# nrf9230_cellcore register map
Vendor: Nordic Semiconductor; Series: nRF92; File version: 1
CPU: CM33 r0p4, little endian, MPU, FPU, 3 interrupt priority bits, 480 interrupts, 8 SAU regions
Registers are 32-bit, read-write, reset 0x0 unless marked. A register's access mark holds for its fields unless they carry their own. Offsets are from the block's base; [hi:lo] are bit positions; lines under a group give offsets from that group; {n}, {i} and the like mark numbered series; 'fields as' and 'values as' point back to an identical list.

## MCPLL_NS — Modem Clock PLL 0
Base 0x44035000
Same registers: MCPLL_S 0x54035000
0x00 TASKS_START wo — Start MCPLL
  [0] TASKS_START
    1=Trigger task
0x04 TASKS_UPDATE wo — Update CONTROL.FRAC and CONTROL.INT values
  [0] TASKS_UPDATE
    1=Trigger task
0x08 TASKS_STOP wo — Cancels the START task. MCPLL may be still enabled if requested by HW.
  [0] TASKS_STOP
    1=Trigger task
0x100 EVENTS_STARTED — MCPLL start sequence completed. Clock is running.
  [0] EVENTS_STARTED
    0=NotGenerated (Event not generated); 1=Generated (Event generated)
0x104 EVENTS_LOCKTIMEOUT — Error event, lock was not achieved in given timeout limit (LOCKTIMEOUT)
  [0] EVENTS_LOCKTIMEOUT
    values as EVENTS_STARTED.EVENTS_STARTED
0x108 EVENTS_LOCKLOST — Error event, MCPLL no longer in lock
  [0] EVENTS_LOCKLOST
    values as EVENTS_STARTED.EVENTS_STARTED
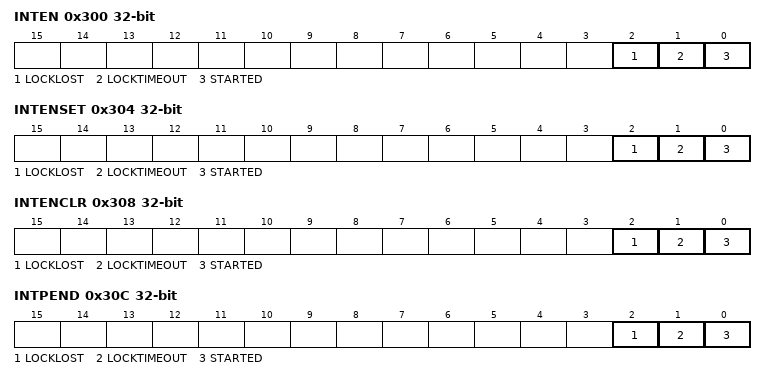
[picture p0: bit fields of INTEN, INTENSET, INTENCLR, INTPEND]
0x300 INTEN — Enable or disable interrupt
  [all] fields
    0=Disabled; 1=Enabled
  [2] LOCKLOST — Enable or disable interrupt for event LOCKLOST
  [1] LOCKTIMEOUT — Enable or disable interrupt for event LOCKTIMEOUT
  [0] STARTED — Enable or disable interrupt for event STARTED
0x304 INTENSET — Enable interrupt
  [all] fields
    on read: 0=Disabled (Read: Disabled); 1=Enabled (Read: Enabled) | on write: 1=Set (Enable)
  [2] LOCKLOST — Write '1' to enable interrupt for event LOCKLOST
  [1] LOCKTIMEOUT — Write '1' to enable interrupt for event LOCKTIMEOUT
  [0] STARTED — Write '1' to enable interrupt for event STARTED
0x308 INTENCLR — Disable interrupt
  [all] fields
    on read: 0=Disabled (Read: Disabled); 1=Enabled (Read: Enabled) | on write: 1=Clear (Disable)
  [2] LOCKLOST — Write '1' to disable interrupt for event LOCKLOST
  [1] LOCKTIMEOUT — Write '1' to disable interrupt for event LOCKTIMEOUT
  [0] STARTED — Write '1' to disable interrupt for event STARTED
0x30C INTPEND ro — Pending interrupts
  [all] fields
    on read: 0=NotPending (Read: Not pending); 1=Pending (Read: Pending)
  [2] LOCKLOST — Read pending status of interrupt for event LOCKLOST
  [1] LOCKTIMEOUT — Read pending status of interrupt for event LOCKTIMEOUT
  [0] STARTED — Read pending status of interrupt for event STARTED
0x400 INLOCK ro — Status bit for MCPLL inlock signal
  [0] INLOCK — MCPLL locked or not
    0=NotInLock (MCPLL not locked); 1=InLock (MCPLL locked)
0x404 REQ_MCPLL_STATUS ro — Status bit for REQ_MCPLL input signal
  [0] REQ_MCPLL_STATUS — MCPLL requested by HW or not
    0=NoRequest (MCPLL not requested by HW); 1=Requested (MCPLL requested by HW)
0x408 FSM_STATUS ro — Current state of MCPLL FSM
  [4:0] FSM_STATUS — state
    0=Idle (No request); 1=StartXo (Request crystal and wait until crystal is settled); 2=StartMcpll (Enable levelshifters and assert SDM digital reset); 3=StartLdo (Enable LDO); 4=StartCore (Enable analog core); 5=StartSdm (Enable sigmadelta modulator); 6=FCWUpdate (Fetch division word from register); 7=FCWSettle (Wait frequency to settle); 8=EnaOutputs (Enable output buffers); 9=Run (Enable lock detector); 10=Ready (Lock detected. Everything ready.); 11=StopLockdet (Disable lock detector); 12=StopSdm (Disable SDM); 13=StopLdo (Disable LDO); 14=StopCore (Disable analog core); 15=StopMcpll (Disable levelshifters and assert SDM digital reset); 16=StopXo (Stop requesting crystal)
0x40C CLEANPWR_ACK ro — Status of the clean power ack
  [0] CLEANPWR_ACK — Status of the clean power ack. Clean power can be requested with CLEANPWR_REQ.
    0=NACK (Clean power not yet available or not requested); 1=ACK (Clean power available)
0x410 HFXO_STATUS ro — Status of the HfXo
  [0] READY — Status of the HfXo.
    0=NotReady (HfXo is not available.); 1=Ready (HfXo ready)
0x504 CONTROL group — Unspecified
  0x00 INT reset 0x12 — Integer part of the control word.
    [5:0] INT — Integer part of the control word
  0x04 FRAC reset 0x199999 — Fractional part of the control word.
    [22:0] FRAC — Fractional part of the control word
0x510 MA reset 0x3 — Post division ratio for OUTA (LTETIMER and CELLRF)
  [2:0] MA
    0=Nothing (Output grounded, constant logic low); 1=CLK307M2 (Division by 16, output frequency is 307.2 MHz); 2=Nothing2 (Output grounded, constant logic low); 3=CLK122M88 (Division by 40, output frequency is 122.88 MHz); 4=CLK153M6 (Division by 32, output frequency is 153.6 MHz); 5=ExtClk (External clock); 6=Nothing3 (Output grounded, constant logic low); 7=Nothing4 (Output grounded, constant logic low)
0x514 MB reset 0x1 — Post division ratio for OUTB (TX DAC in CELLRF)
  [2:0] MB
    0=Nothing (Output grounded, constant logic low); 1=CLK307M2 (Division by 16, output frequency is 307.2 MHz); 2=Nothing2 (Output grounded, constant logic low); 3=Nothing3 (Output grounded, constant logic low); 4=CLK153M6 (Division by 32, output frequency is 153.6 MHz); 5=ExtClk (External clock); 6=Nothing4 (Output grounded, constant logic low); 7=Nothing5 (Output grounded, constant logic low)
0x518 MC reset 0x1 — Post division ratio for OUTC (RX ADC in CELLRF)
  [2:0] MC — Post division ratio for OUTC (RX ADC in CELLRF). Depending on MC_TRIG register a external trigger is required. Changing the division factor between 15 and 16 on the fly is not glitch free. If division factor is switched between 16 and 15 it must be ensured that the receiver of the clock is disabled at that moment.
    0=Nothing (Output grounded, constant logic low); 1=CLK307M2 (Division by 16, output frequency is 307.2 MHz); 2=CLK327M68 (Division by 15, output frequency is 327.68 MHz); 3=Nothing2 (Output grounded, constant logic low); 4=CLK153M6 (Division by 32, output frequency is 153.6 MHz); 5=ExtClk (External clock); 6=Nothing3 (Output grounded, constant logic low); 7=Nothing4 (Output grounded, constant logic low)
0x51C MD — Post division ratio for OUTD (Unused)
  [2:0] MD
    values as MC.MC
0x520 MTESTOUT — Post division ratio for Testout
  [2:0] MTESTOUT — Post division ratio for Testout (Connected to IO)
    0=Nothing (Output grounded, constant logic low); 1=CLK307M2 (Division by 16, output frequency is 307.2 MHz); 2=CLK327M68 (Division by 15, output frequency is 327.68 MHz); 3=CLK122M88 (Division by 40, output frequency is 122.88 MHz); 4=CLK153M6 (Division by 32, output frequency is 153.6 MHz); 5=ExtClk (External clock); 6=Nothing2 (Output grounded, constant logic low); 7=Nothing3 (Output grounded, constant logic low)
0x524 MCTRIG — MC register triggering setting
  [0] MCTRIG_ENA — Enable for MC register triggering
    0=NORMAL (MC register changes division setting immediately); 1=TRIGGER (MC register requires pulse from REQ_MC input before division setting is applied)
0x528 REQUPDATE — REQ_UPDATE setting
  [0] REQ_UPDATE_ENA — Disable for REQ_UPDATE
    0=NORMAL (REQ_UPDATE from HW updates FCW normally); 1=BLOCK (REQ_UPDATE from HW is blocked and doesn`t update FCW)
0x530 TRIM — MCPLL trimming
  [3:0] LDO_RTUNE — LDO reference voltage tuning against process corners. See analog IP specification.
0x534 OVERRIDE group — Override mechanism
  0x00 INLOCK — Override for MCPLL inLock
    [0] FORCEINLOCK — Force inlock value from analog to high
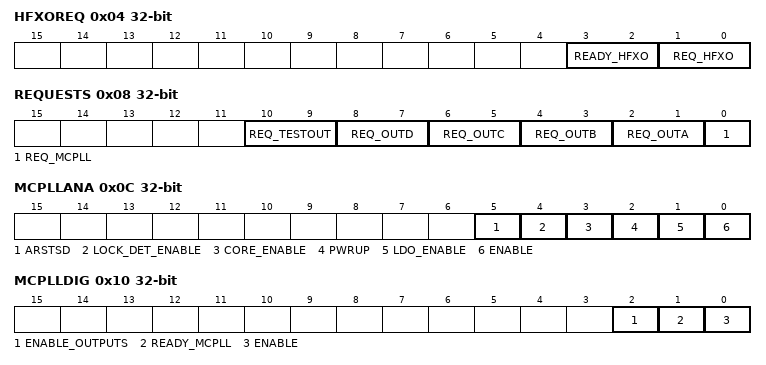
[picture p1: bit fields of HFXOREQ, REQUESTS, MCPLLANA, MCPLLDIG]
  0x04 HFXOREQ — Override for HFXO controls
    [3:2] READY_HFXO — Override for HFXO ready
      0=NORMAL (Ready is provided by crystal to MCPLL FSM); 1=UNUSED (Ready is provided by crystal to MCPLL FSM); 2=BLOCKED (Ready signal from crystal is forced low); 3=FORCED (Ready signal from crystal is forced high)
    [1:0] REQ_HFXO — Override for HFXO request
      0=NORMAL (Crystal is requested according to MCPLL FSM); 1=UNUSED (Crystal is requested according to MCPLL FSM); 2=BLOCKED (Crystal is not requested); 3=FORCED (Crystal is requested)
  0x08 REQUESTS — Override for request signals
    [10:9] REQ_TESTOUT — Override for REQ_TESTOUT
      0=NORMAL (REQ_TESTOUT from HW requests TESTOUT normally); 1=UNUSED (REQ_TESTOUT from HW requests TESTOUT normally); 2=BLOCKED (REQ_TESTOUT from HW is blocked and TESTOUT buffer is disabled); 3=FORCED (REQ_TESTOUT from HW is forced and TESTOUT buffer is enabled)
    [8:7] REQ_OUTD — Override for REQ_OUTD
      0=NORMAL (REQ_OUTD from HW requests OUTD normally); 1=UNUSED (REQ_OUTD from HW requests OUTD normally); 2=BLOCKED (REQ_OUTD from HW is blocked and OUTD buffer is disabled); 3=FORCED (REQ_OUTD from HW is forced and OUTD buffer is enabled)
    [6:5] REQ_OUTC — Override for REQ_OUTC
      0=NORMAL (REQ_OUTC from HW requests OUTC normally); 1=UNUSED (REQ_OUTC from HW requests OUTC normally); 2=BLOCKED (REQ_OUTC from HW is blocked and OUTC buffer is disabled); 3=FORCED (REQ_OUTC from HW is forced and OUTC buffer is enabled)
    [4:3] REQ_OUTB — Override for REQ_OUTB
      0=NORMAL (REQ_OUTB from HW requests OUTB normally); 1=UNUSED (REQ_OUTB from HW requests OUTB normally); 2=BLOCKED (REQ_OUTB from HW is blocked and OUTB buffer is disabled); 3=FORCED (REQ_OUTB from HW is forced and OUTB buffer is enabled)
    [2:1] REQ_OUTA — Override for REQ_OUTA
      0=NORMAL (REQ_OUTA from HW requests OUTA normally); 1=UNUSED (REQ_OUTA from HW requests OUTA normally); 2=BLOCKED (REQ_OUTA from HW is blocked and OUTA buffer is disabled); 3=FORCED (REQ_OUTA from HW is forced and OUTA buffer is enabled)
    [0] REQ_MCPLL — Override for REQ_MCPLL
      0=NORMAL (REQ_MCPLL from HW requests MCPLL normally); 1=BLOCK (REQ_MCPLL from HW is blocked and doesn`t start MCPLL)
  0x0C MCPLLANA — Override for MCPLL analog controls
    [5] ARSTSD — Override for MCPLL sigmadelta modulator reset
      0=OFF (Force ARSTSD low); 1=ON (Force ARSTSD high)
    [4] LOCK_DET_ENABLE — Override for LOCK_DET_ENABLE
      0=OFF (Force LOCK_DET_ENABLE low); 1=ON (Force LOCK_DET_ENABLE high)
    [3] CORE_ENABLE — Override for CORE_ENABLE
      0=OFF (Force CORE_ENABLE low); 1=ON (Force CORE_ENABLE high)
    [2] PWRUP — Override for PWRUP_MCPLL
      0=OFF (Force PWRUP_MCPLL low); 1=ON (Force PWRUP_MCPLL high)
    [1] LDO_ENABLE — LDO enable override value
      0=OFF (Force LDO_ENABLE low); 1=ON (Force LDO_ENABLE high)
    [0] ENABLE — Enable override
      0=No override enabled; 1=Override (All overrides in this register are enabled)
  0x10 MCPLLDIG — Override for MCPLL digital controls
    [2] ENABLE_OUTPUTS — Fsm enableOutputs override
      0=Disabled (Force enableOutputs low); 1=Enabled (Force enableOutputs high)
    [1] READY_MCPLL — Fsm readyMcpll override
      0=LOW (Force readyMcpll low); 1=HIGH (Force readyMcpll high)
    [0] ENABLE — Enable override
      values as OVERRIDE.MCPLLANA.ENABLE
0x550 OUTA_DRV reset 0x1 — Drive strength for OUTA
  [1:0] OUTA_DRV
0x554 OUTB_DRV reset 0x1 — Drive strength for OUTB
  [1:0] OUTB_DRV
0x558 OUTC_DRV reset 0x1 — Drive strength for OUTC
  [1:0] OUTC_DRV
0x55C OUTD_DRV reset 0x1 — Drive strength for OUTD
  [1:0] OUTD_DRV
0x560 OUTTEST_DRV reset 0x1 — Drive strength for Testout
  [1:0] OUTTEST_DRV
0x570 INTMODE — Integer mode
  [0] INTMODE
    0=Fractional mode; 1=Integer mode
0x580 LOCKTIMEOUT — Timeout value for locking
  [1:0] LOCKTIMEOUT
    0=VALUE20US (If locking takes more than 20us, LOCKTIMEOUT event is generated.); 1=VALUE40US (If locking takes more than 40us, LOCKTIMEOUT event is generated.); 2=VALUE60US (If locking takes more than 60us, LOCKTIMEOUT event is generated.); 3=UNLIMITED (Lock signal is waited forever)
0x590 EXTCLK — External clock control
  [0] EXTCLKENABLE — Enable for external clock is input buffer
    0=Disabled (External clock input buffer disabled); 1=Enabled (External clock input buffer enabled)
0x5A0 DBG_DIG — Mmi digital debug control
  [0] RST_CORE — Release synchronous reset from Core domain
    0=Disabled (Normal mode, synchronous reset is requested by MMI); 1=Enabled (Synchronous reset is released)
0x5A4 OUTAEXT_ENA — External clock enable (OUTA)
  [0] OUTAEXT_ENA — External clock enable (OUTA). IMPORTANT: Enable sequence: first OUTAEXT_SEL high, then OUTAEXT_ENA high. Disable sequence: first OUTAEXT_ENA low, then OUTAEXT_SEL low.
    0=Gated (External clock (ckCore) gated); 1=Active (External clock (ckCore) active)
0x5A8 OUTAEXT_SEL — External clock (ckCore) multiplexing to OUTA
  [0] OUTAEXT_SEL — External clock (ckCore) multiplexing to OUTA. IMPORTANT: Enable sequence: first OUTAEXT_SEL high, then OUTAEXT_ENA high. Disable sequence: first OUTAEXT_ENA low, then OUTAEXT_SEL low.
    0=Normal mode, MCPLL provides the clock; 1=External clock (ckCore) selected
0x5AC PWR_CONTROL — Power supply control
  [0] CLEANPWR_REQ — Clean power is requested when MCPLL start is requested. Ack is waited before analog part is enabled.
    0=Disabled (Default supply, clean power is not requested); 1=Enabled (Clean power is requested during MCPLL startup cycle)
0x600 ATB — ATB test bus control
  [3:0] ATE — ATB test bus enable. Writable only in test mode (dftEnable).
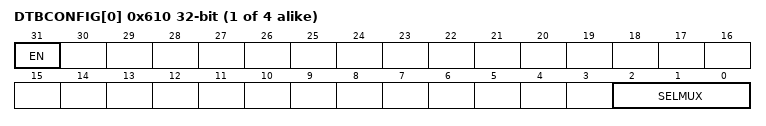
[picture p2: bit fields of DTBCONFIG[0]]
{0x610+4i} DTBCONFIG[{i}] (i=0..3) — Description collection: DTB output n configuration
  [31] EN — Enable the digital test bus
    0=Disabled (Digital test bus is disabled); 1=Enabled (Digital test bus is enabled)
  [2:0] SELMUX — Signal to output on DTBn
    0=VSS (VSS selected); 1=INLOCK selected; 2=reqOutB selected; 3=reqOutC selected; 4=reqOutBOrC (reqOutB 'or' reqOutC selected); 5=readyHfXo selected; 6=reqMcpll selected
0x700 SPARE — Spare signals
  [3:0] SPARE
